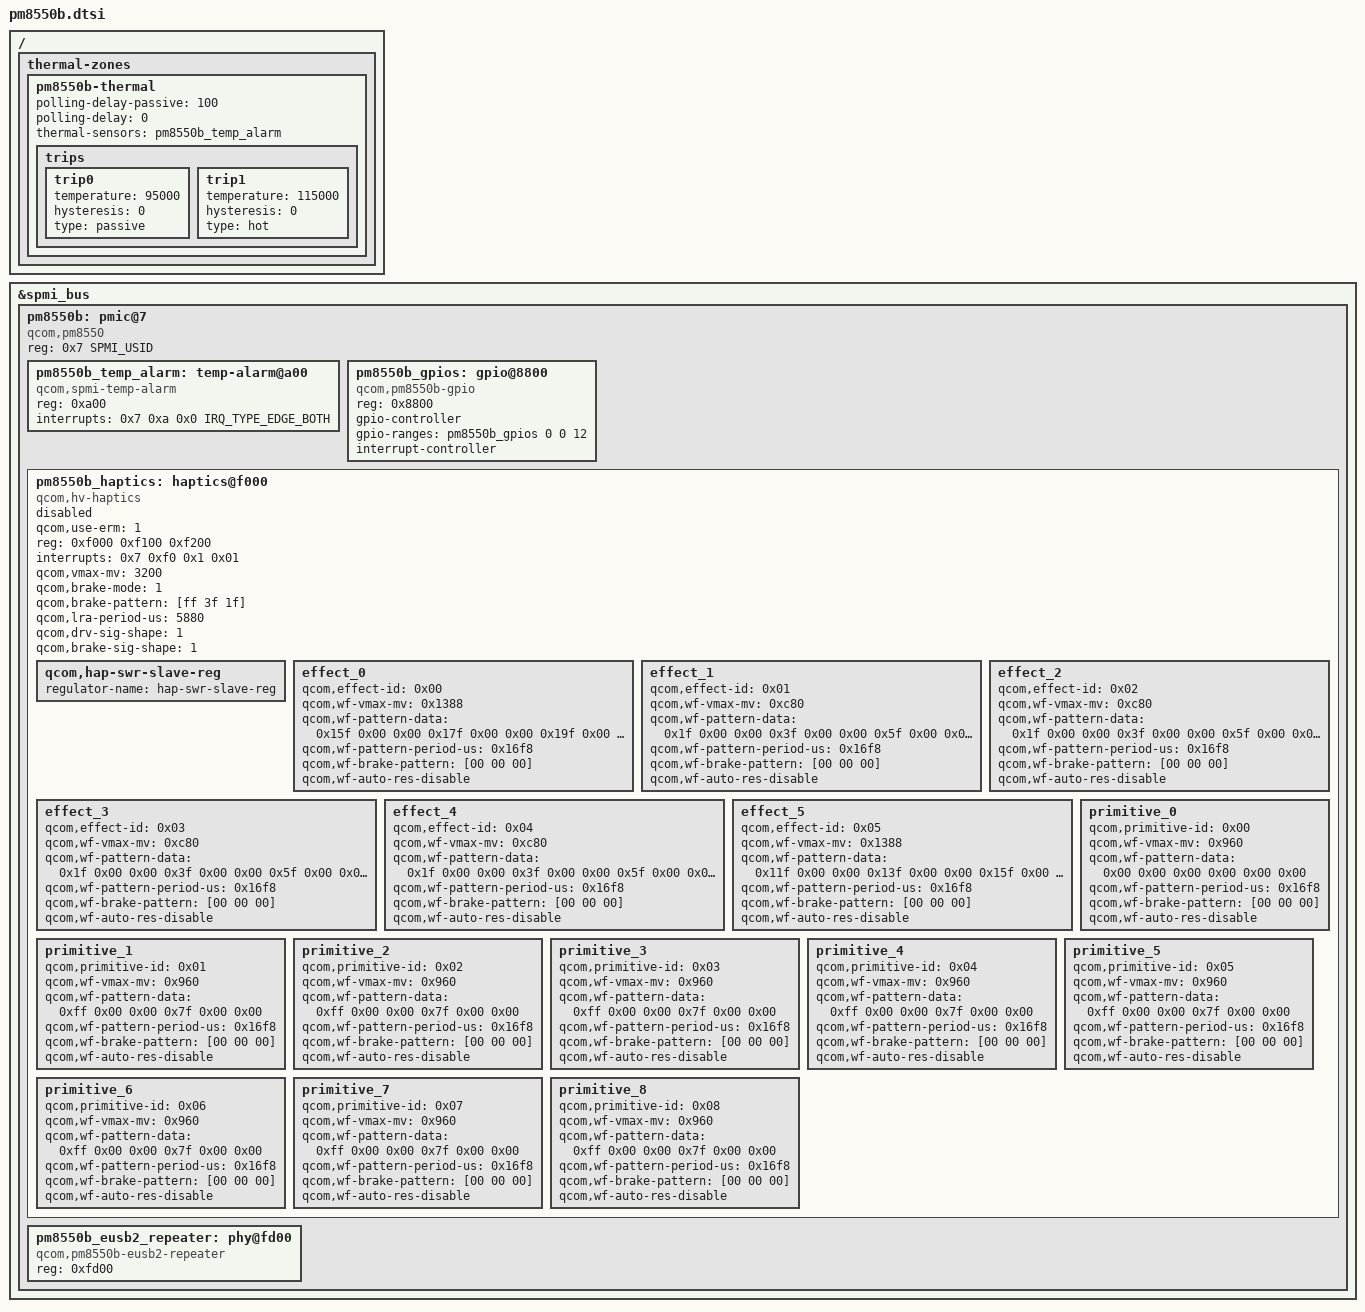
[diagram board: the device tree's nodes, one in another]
// SPDX-License-Identifier: BSD-3-Clause
/*
 * Copyright (c) 2022, Linaro Limited
 */

#include <dt-bindings/interrupt-controller/irq.h>
#include <dt-bindings/spmi/spmi.h>

/ {
	thermal-zones {
		pm8550b-thermal {
			polling-delay-passive = <100>;
			polling-delay = <0>;

			thermal-sensors = <&pm8550b_temp_alarm>;

			trips {
				trip0 {
					temperature = <95000>;
					hysteresis = <0>;
					type = "passive";
				};

				trip1 {
					temperature = <115000>;
					hysteresis = <0>;
					type = "hot";
				};
			};
		};
	};
};


&spmi_bus {
	pm8550b: pmic@7 {
		compatible = "qcom,pm8550", "qcom,spmi-pmic";
		reg = <0x7 SPMI_USID>;
		#address-cells = <1>;
		#size-cells = <0>;

		pm8550b_temp_alarm: temp-alarm@a00 {
			compatible = "qcom,spmi-temp-alarm";
			reg = <0xa00>;
			interrupts = <0x7 0xa 0x0 IRQ_TYPE_EDGE_BOTH>;
			#thermal-sensor-cells = <0>;
		};

		pm8550b_gpios: gpio@8800 {
			compatible = "qcom,pm8550b-gpio", "qcom,spmi-gpio";
			reg = <0x8800>;
			gpio-controller;
			gpio-ranges = <&pm8550b_gpios 0 0 12>;
			#gpio-cells = <2>;
			interrupt-controller;
			#interrupt-cells = <2>;
		};

		pm8550b_haptics: haptics@f000 {
			compatible = "qcom,hv-haptics";
			qcom,use-erm = <1>;
			reg = <0xf000 0xf100 0xf200>;
			interrupts = <0x7 0xf0 0x1 0x01>;
			interrupt-names = "fifo-empty";
			qcom,vmax-mv = <3200>;
			qcom,brake-mode = <1>;
			qcom,brake-pattern = [ff 3f 1f];
			qcom,lra-period-us = <5880>;
			qcom,drv-sig-shape = <1>;
			qcom,brake-sig-shape = <1>;

			status = "disabled";

			qcom,hap-swr-slave-reg {
				regulator-name = "hap-swr-slave-reg";
			};

			effect_0 {
				qcom,effect-id = <0x00>;
				qcom,wf-vmax-mv = <0x1388>;
				qcom,wf-pattern-data = <0x15f 0x00 0x00 0x17f 0x00 0x00 0x19f 0x00 0x00 0x1df 0x00 0x00 0x1df 0x00 0x00 0x19f 0x00 0x00 0x17f 0x00 0x00 0x15f 0x00 0x00>;
				qcom,wf-pattern-period-us = <0x16f8>;
				qcom,wf-brake-pattern = [00 00 00];
				qcom,wf-auto-res-disable;
			};

			effect_1 {
				qcom,effect-id = <0x01>;
				qcom,wf-vmax-mv = <0xc80>;
				qcom,wf-pattern-data = <0x1f 0x00 0x00 0x3f 0x00 0x00 0x5f 0x00 0x00 0x7f 0x00 0x00 0x17f 0x00 0x00 0x15f 0x00 0x00 0x13f 0x00 0x00 0x11f 0x00 0x00>;
				qcom,wf-pattern-period-us = <0x16f8>;
				qcom,wf-brake-pattern = [00 00 00];
				qcom,wf-auto-res-disable;
			};

			effect_2 {
				qcom,effect-id = <0x02>;
				qcom,wf-vmax-mv = <0xc80>;
				qcom,wf-pattern-data = <0x1f 0x00 0x00 0x3f 0x00 0x00 0x5f 0x00 0x00 0x7f 0x00 0x00 0x17f 0x00 0x00 0x15f 0x00 0x00 0x13f 0x00 0x00 0x11f 0x00 0x00>;
				qcom,wf-pattern-period-us = <0x16f8>;
				qcom,wf-brake-pattern = [00 00 00];
				qcom,wf-auto-res-disable;
			};

			effect_3 {
				qcom,effect-id = <0x03>;
				qcom,wf-vmax-mv = <0xc80>;
				qcom,wf-pattern-data = <0x1f 0x00 0x00 0x3f 0x00 0x00 0x5f 0x00 0x00 0x7f 0x00 0x00 0x17f 0x00 0x00 0x15f 0x00 0x00 0x13f 0x00 0x00 0x11f 0x00 0x00>;
				qcom,wf-pattern-period-us = <0x16f8>;
				qcom,wf-brake-pattern = [00 00 00];
				qcom,wf-auto-res-disable;
			};

			effect_4 {
				qcom,effect-id = <0x04>;
				qcom,wf-vmax-mv = <0xc80>;
				qcom,wf-pattern-data = <0x1f 0x00 0x00 0x3f 0x00 0x00 0x5f 0x00 0x00 0x7f 0x00 0x00 0x17f 0x00 0x00 0x15f 0x00 0x00 0x13f 0x00 0x00 0x11f 0x00 0x00>;
				qcom,wf-pattern-period-us = <0x16f8>;
				qcom,wf-brake-pattern = [00 00 00];
				qcom,wf-auto-res-disable;
			};

			effect_5 {
				qcom,effect-id = <0x05>;
				qcom,wf-vmax-mv = <0x1388>;
				qcom,wf-pattern-data = <0x11f 0x00 0x00 0x13f 0x00 0x00 0x15f 0x00 0x00 0x17f 0x00 0x00 0x17f 0x00 0x00 0x15f 0x00 0x00 0x13f 0x00 0x00 0x11f 0x00 0x00>;
				qcom,wf-pattern-period-us = <0x16f8>;
				qcom,wf-brake-pattern = [00 00 00];
				qcom,wf-auto-res-disable;
			};

			primitive_0 {
				qcom,primitive-id = <0x00>;
				qcom,wf-vmax-mv = <0x960>;
				qcom,wf-pattern-data = <0x00 0x00 0x00 0x00 0x00 0x00>;
				qcom,wf-pattern-period-us = <0x16f8>;
				qcom,wf-brake-pattern = [00 00 00];
				qcom,wf-auto-res-disable;
			};

			primitive_1 {
				qcom,primitive-id = <0x01>;
				qcom,wf-vmax-mv = <0x960>;
				qcom,wf-pattern-data = <0xff 0x00 0x00 0x7f 0x00 0x00>;
				qcom,wf-pattern-period-us = <0x16f8>;
				qcom,wf-brake-pattern = [00 00 00];
				qcom,wf-auto-res-disable;
			};

			primitive_2 {
				qcom,primitive-id = <0x02>;
				qcom,wf-vmax-mv = <0x960>;
				qcom,wf-pattern-data = <0xff 0x00 0x00 0x7f 0x00 0x00>;
				qcom,wf-pattern-period-us = <0x16f8>;
				qcom,wf-brake-pattern = [00 00 00];
				qcom,wf-auto-res-disable;
			};

			primitive_3 {
				qcom,primitive-id = <0x03>;
				qcom,wf-vmax-mv = <0x960>;
				qcom,wf-pattern-data = <0xff 0x00 0x00 0x7f 0x00 0x00>;
				qcom,wf-pattern-period-us = <0x16f8>;
				qcom,wf-brake-pattern = [00 00 00];
				qcom,wf-auto-res-disable;
			};

			primitive_4 {
				qcom,primitive-id = <0x04>;
				qcom,wf-vmax-mv = <0x960>;
				qcom,wf-pattern-data = <0xff 0x00 0x00 0x7f 0x00 0x00>;
				qcom,wf-pattern-period-us = <0x16f8>;
				qcom,wf-brake-pattern = [00 00 00];
				qcom,wf-auto-res-disable;
			};

			primitive_5 {
				qcom,primitive-id = <0x05>;
				qcom,wf-vmax-mv = <0x960>;
				qcom,wf-pattern-data = <0xff 0x00 0x00 0x7f 0x00 0x00>;
				qcom,wf-pattern-period-us = <0x16f8>;
				qcom,wf-brake-pattern = [00 00 00];
				qcom,wf-auto-res-disable;
			};

			primitive_6 {
				qcom,primitive-id = <0x06>;
				qcom,wf-vmax-mv = <0x960>;
				qcom,wf-pattern-data = <0xff 0x00 0x00 0x7f 0x00 0x00>;
				qcom,wf-pattern-period-us = <0x16f8>;
				qcom,wf-brake-pattern = [00 00 00];
				qcom,wf-auto-res-disable;
			};

			primitive_7 {
				qcom,primitive-id = <0x07>;
				qcom,wf-vmax-mv = <0x960>;
				qcom,wf-pattern-data = <0xff 0x00 0x00 0x7f 0x00 0x00>;
				qcom,wf-pattern-period-us = <0x16f8>;
				qcom,wf-brake-pattern = [00 00 00];
				qcom,wf-auto-res-disable;
			};

			primitive_8 {
				qcom,primitive-id = <0x08>;
				qcom,wf-vmax-mv = <0x960>;
				qcom,wf-pattern-data = <0xff 0x00 0x00 0x7f 0x00 0x00>;
				qcom,wf-pattern-period-us = <0x16f8>;
				qcom,wf-brake-pattern = [00 00 00];
				qcom,wf-auto-res-disable;
			};
		};

		pm8550b_eusb2_repeater: phy@fd00 {
			compatible = "qcom,pm8550b-eusb2-repeater";
			reg = <0xfd00>;
			#phy-cells = <0>;
		};
	};
};
